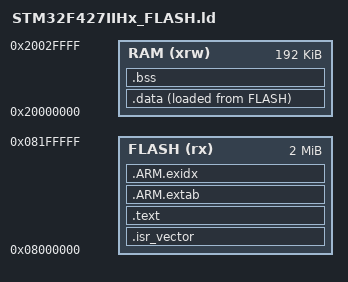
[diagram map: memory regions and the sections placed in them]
ENTRY(Reset_Handler)

MEMORY
{
  FLASH (rx) : ORIGIN = 0x08000000, LENGTH = 2048K
  RAM (xrw)  : ORIGIN = 0x20000000, LENGTH = 192K
}

_estack = ORIGIN(RAM) + LENGTH(RAM);

SECTIONS
{
  .isr_vector :
  {
    KEEP(*(.isr_vector))
  } > FLASH

  .text :
  {
    *(.text*)
    *(.rodata*)
    KEEP(*(.init))
    KEEP(*(.fini))
    _etext = .;
  } > FLASH

  .ARM.extab :
  {
    *(.ARM.extab* .gnu.linkonce.armextab.*)
  } > FLASH

  .ARM.exidx :
  {
    __exidx_start = .;
    *(.ARM.exidx* .gnu.linkonce.armexidx.*)
    __exidx_end = .;
  } > FLASH

  _sidata = LOADADDR(.data);

  .data :
  {
    . = ALIGN(4);
    _sdata = .;
    *(.data*)
    . = ALIGN(4);
    _edata = .;
  } > RAM AT > FLASH

  .bss :
  {
    . = ALIGN(4);
    _sbss = .;
    *(.bss*)
    *(COMMON)
    . = ALIGN(4);
    _ebss = .;
  } > RAM

  /DISCARD/ :
  {
    libc.a(*)
    libm.a(*)
    libgcc.a(*)
  }
}
